# ADSP-SC83xW_HPC register map
Vendor: Analog Devices; Series: ADSP-SC83xW_HPC; File version: 3.0.3.517
CPU: 
Registers are 32-bit, read-write, reset 0x0 unless marked. A register's access mark holds for its fields unless they carry their own. Offsets are from the block's base; [hi:lo] are bit positions.

## TWI0 — Two-Wire Interface
Base 0x31001400
Same registers: TWI3 0x31001000, TWI4 0x31001100, TWI5 0x31001200, TWI1 0x31001500, TWI2 0x31001600
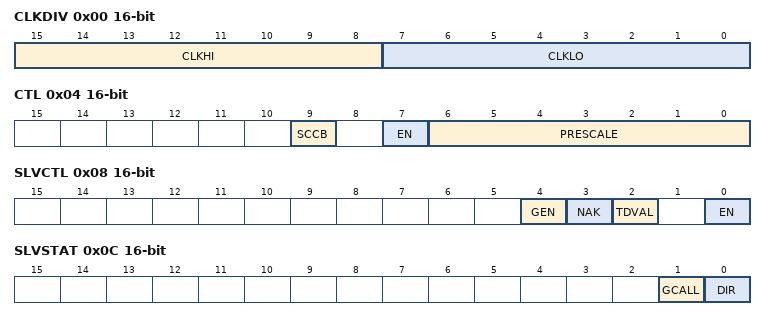
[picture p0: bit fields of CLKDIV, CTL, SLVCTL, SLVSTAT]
0x00 CLKDIV 16-bit — SCL Clock Divider Register
  [15:8] CLKHI range 0x00000000..0x000000FF — SCL Clock High Periods
  [7:0] CLKLO range 0x00000000..0x000000FF — SCL Clock Low Periods
0x04 CTL 16-bit — Control Register
  [9] SCCB — SCCB Compatibility
    0=SCCB_DIS (Disable SCCB compatibility.); 1=SCCB_EN (Enable SCCB compatibility.)
  [7] EN — Enable Module
    0=DIS (Disable); 1=EN (Enable)
  [6:0] PRESCALE range 0x00000000..0x0000007F — SCLK Prescale Value
0x08 SLVCTL 16-bit — Target Mode Control Register
  [4] GEN — General Call Enable
    0=GDIS (Disable General Call Matching); 1=GEN (Enable General Call Matching)
  [3] NAK — Not Acknowledge
    0=ACKGEN (Generate ACK); 1=NAKGEN (Generate NAK)
  [2] TDVAL — Transmit Data Valid for Target
    0=INVALID (Data Invalid for Completer Tx); 1=VALID (Data Valid for Completer Tx)
  [0] EN — Enable Target Mode
    0=DIS (Disable); 1=EN (Enable)
0x0C SLVSTAT 16-bit — Target Mode Status Register
  [1] GCALL ro — General Call
    0=NO (Not a General Call Address); 1=YES (General Call Address)
  [0] DIR ro — Transfer Direction for Target
    0=RX (Completer Receive); 1=TX (Completer Transmit)
0x10 SLVADDR 16-bit — Target Mode Address Register
  [6:0] ADDR range 0x00000000..0x0000007F — Target Mode Address
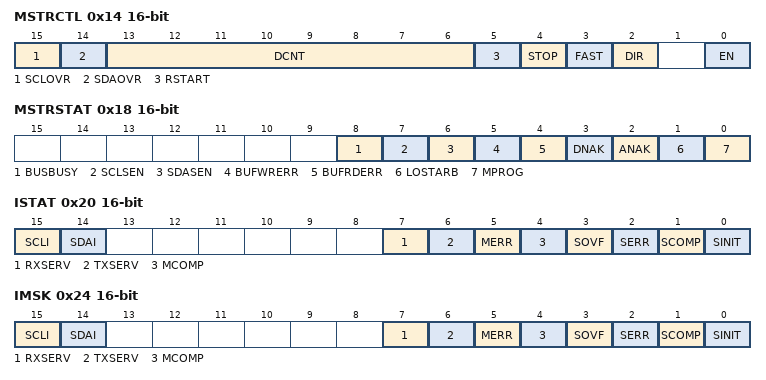
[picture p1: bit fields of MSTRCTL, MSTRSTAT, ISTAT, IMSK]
0x14 MSTRCTL 16-bit — Controller Mode Registers
  [15] SCLOVR — Serial Clock Override
    0=SCLNORM (Permit Normal SCL Operation); 1=SCLOVER (Override Normal SCL Operation)
  [14] SDAOVR — Serial Data Override
    0=SDANORM (Permit Normal SDA Operation); 1=SDAOVER (Override Normal SDA Operation)
  [13:6] DCNT range 0x00000000..0x000000FF — Data Transfer Count
  [5] RSTART — Repeat Start
    0=END (Disable Repeat Start); 1=RPT (Enable Repeat Start)
  [4] STOP — Issue Stop Condition
    0=NORM (Permit Normal Operation); 1=STOP (Issue Stop)
  [3] FAST — Fast Mode
    0=SMODE (Select Standard Mode); 1=FAST (Select Fast Mode)
  [2] DIR — Transfer Direction for Controller
    0=TX (Requester Transmit); 1=RX (Requester Receive)
  [0] EN — Enable Controller Mode
    0=DIS (Disable); 1=EN (Enable)
0x18 MSTRSTAT 16-bit — Controller Mode Status Register
  [8] BUSBUSY ro
    0=FREE (Bus Free.); 1=BUSY (Bus Busy.)
  [7] SCLSEN ro — Serial Clock Sense
    0=SCLSEN_NO (SCL Inactive "One".); 1=SCLSEN_YES (SCL Active "Zero".)
  [6] SDASEN ro — Serial Data Sense
    0=SDASEN_NO (SDA Inactive "One".); 1=SDASEN_YES (SDA Active "Zero".)
  [5] BUFWRERR — Buffer Write Error
    0=BUFWRERR_NO (No Status); 1=BUFWRERR_YES (Buffer Write Error)
  [4] BUFRDERR — Buffer Read Error
    0=BUFRDERR_NO (No Status); 1=BUFRDERR_YES (Buffer Read Error)
  [3] DNAK — Data Not Acknowledged
    0=DNAK_NO (No Status); 1=DNAK_YES (Data NAK)
  [2] ANAK — Address Not Acknowledged
    0=ANAK_NO (No Status); 1=ANAK_YES (Address NAK)
  [1] LOSTARB — Lost Arbitration
    0=LOSTARB_NO (No Status); 1=LOSTARB_YES (Lost Arbitration)
  [0] MPROG ro — Controller Transfer in Progress
    0=MPROG_NO (No Status); 1=MPROG_YES (Requester Transfer in Progress)
0x1C MSTRADDR 16-bit — Controller Mode Address Register
  [6:0] ADDR range 0x00000000..0x0000007F — Controller Mode Address
0x20 ISTAT 16-bit — Interrupt Status Register
  [15] SCLI — Serial Clock Interrupt
    0=SCLI_NO (No Interrupt.); 1=SCLI_YES (Interrupt Detected.)
  [14] SDAI — Serial Data Interrupt
    0=SDAI_NO (No Interrupt.); 1=SDAI_YES (Interrupt Detected.)
  [7] RXSERV — Rx FIFO Service
    0=RXSERV_NO (No Interrupt.); 1=RXSERV_YES (Interrupt Detected.)
  [6] TXSERV — Tx FIFO Service
    0=TXSERV_NO (No Interrupt.); 1=TXSERV_YES (Interrupt Detected.)
  [5] MERR — Controller Transfer Error
    0=MERR_NO (No Interrupt); 1=MERR_YES (Interrupt Detected)
  [4] MCOMP — Controller Transfer Complete
    0=MCOMP_NO (No Interrupt); 1=MCOMP_YES (Interrupt Detected)
  [3] SOVF — Target Overflow
    0=SOVF_NO (No Interrupt); 1=SOVF_YES (Interrupt Detected)
  [2] SERR — Target Transfer Error
    0=SERR_NO (No Interrupt); 1=SERR_YES (Interrupt Detected)
  [1] SCOMP — Target Transfer Complete
    0=SCOMP_NO (No Interrupt); 1=SCOMP_YES (Interrupt Detected)
  [0] SINIT — Target Transfer Initiated
    0=SINIT_NO (No Interrupt.); 1=SINIT_YES (Interrupt Detected.)
0x24 IMSK 16-bit — Interrupt Mask Register
  [15] SCLI — Serial Clock Interrupt Mask
    0=SCLI_MSK (Mask (Disable) Interrupt); 1=SCLI_UMSK (Unmask (Enable) Interrupt)
  [14] SDAI — Serial Data Interrupt Mask
    0=SDAI_MSK (Mask (Disable) Interrupt); 1=SDAI_UMSK (Unmask (Enable) Interrupt)
  [7] RXSERV — Rx FIFO Service Interrupt Mask
    0=RXSERV_MSK (Mask (Disable) Interrupt); 1=RXSERV_UMSK (Unmask (Enable) Interrupt)
  [6] TXSERV — Tx FIFO Service Interrupt Mask
    0=TXSERV_MSK (Mask (Disable) Interrupt); 1=TXSERV_UMSK (Unmask (Enable) Interrupt)
  [5] MERR — Controller Transfer Error Interrupt Mask
    0=MERR_MSK (Mask (Disable) Interrupt); 1=MERR_UMSK (Unmask (Enable) Interrupt)
  [4] MCOMP — Controller Transfer Complete Interrupt Mask
    0=MCOMP_MSK (Mask (Disable) Interrupt); 1=MCOMP_UMSK (Unmask (Enable) Interrupt)
  [3] SOVF — Target Overflow Interrupt Mask
    0=SOVF_MSK (Mask (Disable) Interrupt); 1=SOVF_UMSK (Unmask (Enable) Interrupt)
  [2] SERR — Target Transfer Error Interrupt Mask
    0=SERR_MSK (Mask (Disable) Interrupt); 1=SERR_UMSK (Unmask (Enable) Interrupt)
  [1] SCOMP — Target Transfer Complete Interrupt Mask
    0=SCOMP_MSK (Mask (Disable) Interrupt); 1=SCOMP_UMSK (Unmask (Enable) Interrupt)
  [0] SINIT — Target Transfer Initiated Interrupt Mask
    0=SINIT_MSK (Mask (Disable) Interrupt); 1=SINIT_UMSK (Unmask (Enable) Interrupt)
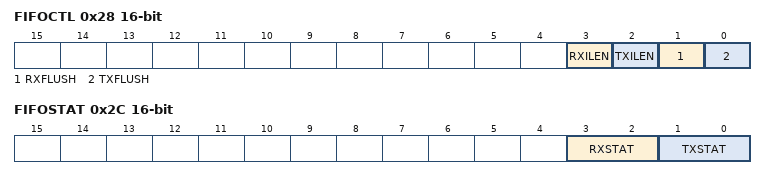
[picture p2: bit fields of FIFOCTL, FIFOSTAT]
0x28 FIFOCTL 16-bit — FIFO Control Register
  [3] RXILEN — Rx Buffer Interrupt Length
    0=RXONEBYTE (RXSERVI on 1 or 2 Bytes in FIFO); 1=RXTWOBYTE (RXSERVI on 2 Bytes in FIFO)
  [2] TXILEN — Tx Buffer Interrupt Length
    0=TXONEBYTE (TXSERVI on 1 Byte of FIFO Empty); 1=TXTWOBYTE (TXSERVI on 2 Bytes of FIFO Empty)
  [1] RXFLUSH — Rx Buffer Flush
    0=RXNORM (Normal Operation of Rx Buffer); 1=RXFLUSH (Flush Rx Buffer)
  [0] TXFLUSH — Tx Buffer Flush
    0=TXNORM (Normal Operation of Tx Buffer); 1=TXFLUSH (Flush Tx Buffer)
0x2C FIFOSTAT 16-bit — FIFO Status Register
  [3:2] RXSTAT ro — Rx FIFO Status
  [1:0] TXSTAT ro — Tx FIFO Status
0x80 TXDATA8 16-bit — Tx Data Single-Byte Register
  [7:0] VALUE range 0x00000000..0x000000FF — Tx Data 8-Bit Value
0x84 TXDATA16 16-bit — Tx Data Double-Byte Register
  [15:0] VALUE range 0x00000000..0x0000FFFF — Tx Data 16-Bit Value
0x88 RXDATA8 16-bit — Rx Data Single-Byte Register
  [7:0] VALUE range 0x00000000..0x000000FF — Rx Data 8-Bit Value
0x8C RXDATA16 16-bit — Rx Data Double-Byte Register
  [15:0] VALUE range 0x00000000..0x0000FFFF — Rx Data 16-Bit Value
